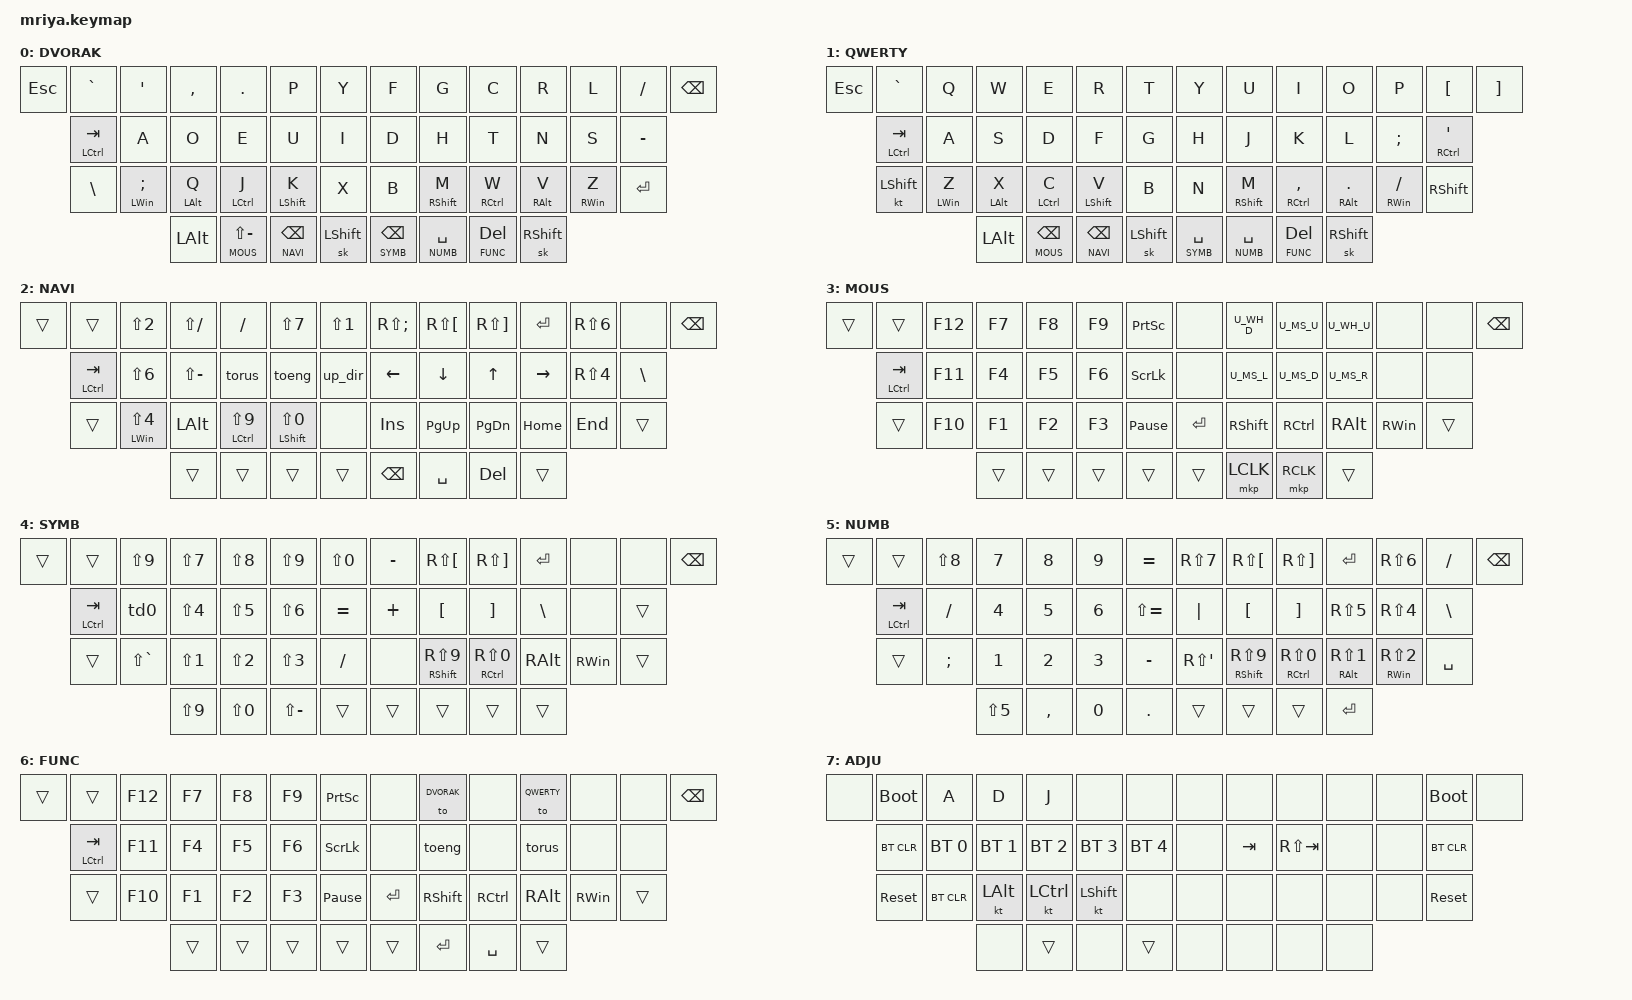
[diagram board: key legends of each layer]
#include <dt-bindings/zmk/bt.h>
#include <dt-bindings/zmk/keys.h>
#include <behaviors.dtsi>
#include "keypos_46keys_mriya.h"
#include "mouse.dtsi"

#define DVORAK 0
#define QWERTY 1
#define NAVI 2
#define MOUS 3
#define SYMB 4
#define NUMB 5
#define FUNC 6
#define ADJU 7

#define XXX &none
#define ___ &trans

#define QUICK_TAP_MS 175

&sk {  // sticky-key config
    release-after-ms = <900>;  // release after 0.6s
    quick-release;             // no double capitalization when rolling keys
};

&sl {  // sticky-layer config
    ignore-modifiers;          // allow chording sticky mods & layers
};

&lt {  // layer-tap config
    flavor = "balanced";
    tapping-term-ms = <200>;
    quick-tap-ms = <QUICK_TAP_MS>;
};

/* Homerow mods */

#define KEYS_L LT0 LT1 LT2 LT3 LT4 LT5 LM0 LM1 LM2 LM3 LM4 LM5 LB0 LB1 LB2 LB3 LB4 LB5 // left hand
#define KEYS_R RT0 RT1 RT2 RT3 RT4 RT5 RM0 RM1 RM2 RM3 RM4 RM5 RB0 RB1 RB2 RB3 RB4 RB5 // right hand
#define THUMBS LH3 LH2 LH1 LH0 RH0 RH1 RH2 RH3                                         // thumbs

/ {
    macros {
        assign: assign {
            label = "assign";
            compatible = "zmk,behavior-macro";
            #binding-cells = <0>;
            bindings = <&macro_tap>, <&kp COLON &kp EQUAL &kp SPACE>;
        };
        up_dir: up_dir {
            label = "up_dir";
            compatible = "zmk,behavior-macro";
            #binding-cells = <0>;
            bindings = <&macro_tap>, <&kp DOT &kp DOT &kp SLASH>;
        };
        torus: torus {
            label = "torus";
            compatible = "zmk,behavior-macro";
            #binding-cells = <0>;
            bindings = <&macro_tap>, <&to QWERTY>, <&kp LA(LSHFT)>;
        };
        toeng: toeng {
            label = "toeng";
            compatible = "zmk,behavior-macro";
            #binding-cells = <0>;
            bindings = <&macro_tap>, <&to DVORAK>, <&kp LA(LSHFT)>;
        };
    };

    combos {
        compatible = "zmk,combos";
        combo_qmark {
            timeout-ms = <50>;
            layers = <QWERTY>;
            key-positions = <LM2 LM3>;
            require-prior-idle-ms = <150>;
            bindings = <&kp AMPS>; /* qmark in russian map */
        };
        combo_excl {
            timeout-ms = <50>;
            layers = <QWERTY>;
            key-positions = <17 18>;
            require-prior-idle-ms = <150>;
            bindings = <&kp EXCL>;
        };
        combo_commaRus {
            timeout-ms = <50>;
            layers = <QWERTY>;
            key-positions = <21 22>;
            require-prior-idle-ms = <150>;
            bindings = <&kp QMARK>; /* comma in russian map */
        };
        combo_dotRus {
            timeout-ms = <50>;
            layers = <QWERTY>;
            key-positions = <22 23>;
            require-prior-idle-ms = <150>;
            bindings = <&kp FSLH>; /* dot in russian map */
        };

        combo_esc {
            timeout-ms = <18>;
            key-positions = <LT2 LT3>;
            require-prior-idle-ms = <150>;
            bindings = <&kp ESC>;
        };
        combo_enter {
            timeout-ms = <18>;
            key-positions = <4 5>;
            require-prior-idle-ms = <150>;
            bindings = <&kp ENTER>;
        };
//        combo_tab {
//            timeout-ms = <18>;
//            key-positions = <LM2 LM3>;
//            require-prior-idle-ms = <150>;
//            bindings = <&kp TAB>;
//        };
        combo_assign {
            timeout-ms = <18>;
            key-positions = <LM2 LM3>;
            require-prior-idle-ms = <150>;
            bindings = <&assign>;
        };
        combo_del {
            timeout-ms = <18>;
            key-positions = <RT1 RT2>;
            require-prior-idle-ms = <150>;
            bindings = <&kp DEL>;
        };
        combo_bspc {
            timeout-ms = <18>;
            key-positions = <RT2 RT3>;
            require-prior-idle-ms = <150>;
            bindings = <&kp BSPC>;
        };

        combo_lpar {
            timeout-ms = <30>;
            key-positions = <RM1 RM2>;
            require-prior-idle-ms = <150>;
            bindings = <&kp LPAR>;
        };
        combo_rpar {
            timeout-ms = <30>;
            key-positions = <RM2 RM3>;
            require-prior-idle-ms = <150>;
            bindings = <&kp RPAR>;
        };

        combo_pipe {
            timeout-ms = <30>;
            key-positions = <RM3 RB3>;
            require-prior-idle-ms = <150>;
            bindings = <&kp PIPE>;
        };
    };

    behaviors {
        td0: tap_dance_0 {
            label = "td0";
            compatible = "zmk,behavior-tap-dance";
            #binding-cells = <0>;
            tapping-term-ms = <250>;
            bindings = <&kp COLON>, <&assign>;
        };
        bhl: balanced_homerow_left {
            label = "bhl";
            compatible = "zmk,behavior-hold-tap";
            #binding-cells = <2>;
        flavor = "balanced";
        tapping-term-ms = <280>;
        quick-tap-ms = <QUICK_TAP_MS>;
        require-prior-idle-ms = <150>;
        bindings = <&kp>, <&kp>;
        hold-trigger-key-positions = <7 8 9 10 11 12 13 20 21 22 23 24 25 32 33 34 35 36 37 42 43 44 45>;
        hold-trigger-on-release;
/*            tapping-term-ms = <300>;
            quick-tap-ms = <175>;
            require-prior-idle-ms = <150>;
            flavor = "balanced";
            bindings = <&kp>, <&kp>;
            hold-trigger-key-positions = <7 8 9 10 11 12 13 20 21 22 23 24 25 32 33 34 35 36 37 42 43 44 45>;
            hold-trigger-on-release; */
        };
        bhr: balanced_homerow_right {
            label = "bhr";
            compatible = "zmk,behavior-hold-tap";
            #binding-cells = <2>;
        flavor = "balanced";
        tapping-term-ms = <280>;
        quick-tap-ms = <QUICK_TAP_MS>;
        require-prior-idle-ms = <150>;
        bindings = <&kp>, <&kp>;
        hold-trigger-key-positions = <0 1 2 3 4 5 6 14 15 16 17 18 19 26 27 28 29 30 31 38 39 40 41>;
        hold-trigger-on-release;
/*            tapping-term-ms = <300>;
            quick-tap-ms = <175>;
            require-prior-idle-ms = <150>;
            flavor = "balanced";
            bindings = <&kp>, <&kp>;
            hold-trigger-key-positions = <0 1 2 3 4 5 6 14 15 16 17 18 19 26 27 28 29 30 31 38 39 40 41>;
            hold-trigger-on-release; */
        };
        mo_tog: behavior_mo_tog {
            label = "mo_tog";
            compatible = "zmk,behavior-hold-tap";
            #binding-cells = <2>;
            flavor = "hold-preferred";
            tapping-term-ms = <200>;
            bindings = <&mo>, <&tog>;
        };
    };

    conditional_layers {
        compatible = "zmk,conditional-layers";
        tri_layer {
            if-layers = <MOUS FUNC>;
            then-layer = <ADJU>;
        };
    };

    keymap {
        compatible = "zmk,keymap";

        DVORAK {
            bindings = <
&kp ESC  &kp GRAVE      &kp SQT         &kp COMMA      &kp DOT             &kp P          &kp Y                &kp F           &kp G           &kp C          &kp R        &kp L           &kp SLASH          &kp BSPC
         &mt LCTRL TAB  &kp A           &kp O          &kp E               &kp U          &kp I                &kp D           &kp H           &kp T          &kp N        &kp S           &kp MINUS
         &kp BSLH       &bhl LWIN SEMI  &bhl LALT Q    &bhl LCTRL J        &bhl LSHFT K   &kp X                &kp B           &bhr RSHFT M    &bhr RCTRL W   &bhr RALT V  &bhr RWIN Z     &kp ENTER
                                        &kp LALT       &lt MOUS LS(MINUS)  &lt NAVI BSPC  &sk LSHFT            &lt SYMB BSPC   &lt NUMB SPACE  &lt FUNC DEL   &sk RSHFT
            >;
        };

        QWERTY {
            bindings = <
&kp ESC  &kp GRAVE      &kp Q           &kp W          &kp E          &kp R          &kp T                     &kp Y           &kp U           &kp I             &kp O          &kp P           &kp LBKT      &kp RBKT
         &mt LCTRL TAB  &kp A           &kp S          &kp D          &kp F          &kp G                     &kp H           &kp J           &kp K             &kp L          &kp SEMI        &mt RCTRL SQT
         &kt LSHFT      &bhl LWIN Z     &bhl LALT X    &bhl LCTRL C   &bhl LSHFT V   &kp B                     &kp N           &bhr RSHFT M    &bhr RCTRL COMMA  &bhr RALT DOT  &bhr RWIN FSLH  &kp RSHFT
                                        &kp LALT       &lt MOUS BSPC  &lt NAVI BSPC  &sk LSHFT                 &lt SYMB SPACE  &lt NUMB SPACE  &lt FUNC DEL      &sk RSHFT  
            >;
        };

        NAVI {
// for russian layout
// S(KC_4) -> ;    S(KC_2) -> "    KC_SLSH -> .   S(KC_SLSH) -> ,  S(KC_7) -> ?    S(KC_1) -> !   S(KC_6) -> :
            bindings = <
&trans   &trans         &kp LS(N2)        &kp LS(SLASH)  &kp SLASH          &kp LS(N7)         &kp LS(N1)      &kp RS(SEMI)  &kp RS(LBKT)    &kp RS(RBKT)      &kp ENTER      &kp RS(N6)      &none           &kp BSPC
         &mt LCTRL TAB  &kp LS(N6)        &kp LS(MINUS)  &torus             &toeng             &up_dir         &kp LEFT      &kp DOWN        &kp UP            &kp RIGHT      &kp RS(N4)      &kp BSLH
         &trans         &bhl LWIN LS(N4)  &kp LALT       &bhl LCTRL LS(N9)  &bhl LSHFT LS(N0)  &none           &kp INS       &kp PG_UP       &kp PG_DN         &kp HOME       &kp END         &trans
                                          &trans         &trans             &trans             &trans          &kp BSPC      &kp SPACE       &kp DEL           &trans
            >;
        };

        MOUS {
            bindings = <
&trans   &trans         &kp F12         &kp F7         &kp F8         &kp F9         &kp PSCRN                 &none         U_WH_D         U_MS_U             U_WH_U         &none           &none           &kp BSPC
         &mt LCTRL TAB  &kp F11         &kp F4         &kp F5         &kp F6         &kp SLCK                  &none         U_MS_L         U_MS_D             U_MS_R         &none           &none
         &trans         &kp F10         &kp F1         &kp F2         &kp F3         &kp PAUSE_BREAK           &kp ENTER     &kp RSHFT      &kp RCTRL          &kp RALT       &kp RWIN        &trans
                                        &trans         &trans         &trans         &trans                    &trans        &mkp LCLK      &mkp RCLK          &trans
            >;
        };

        SYMB {
            bindings = <
&trans   &trans         &kp LS(N9)      &kp LS(N7)     &kp LS(N8)     &kp LS(N9)     &kp LS(N0)                &kp MINUS    &kp RS(LBKT)       &kp RS(RBKT)       &kp ENTER      &none           &none            &kp BSPC
         &mt LCTRL TAB  &td0            &kp LS(N4)     &kp LS(N5)     &kp LS(N6)     &kp EQUAL                 &kp PLUS     &kp LBKT           &kp RBKT           &kp BSLH       &none           &trans
         &trans         &kp LS(GRAVE)   &kp LS(N1)     &kp LS(N2)     &kp LS(N3)     &kp SLASH                 &none        &bhr RSHFT RS(N9)  &bhr RCTRL RS(N0)  &kp RALT       &kp RWIN        &trans
                                        &kp LS(N9)     &kp LS(N0)     &kp LS(MINUS)  &trans                    &trans       &trans             &trans             &trans
            >;
        };

        NUMB {
            bindings = <
&trans   &trans         &kp LS(N8)      &kp N7         &kp N8         &kp N9         &kp EQUAL                 &kp RS(N7)   &kp RS(LBKT)       &kp RS(RBKT)       &kp ENTER         &kp RS(N6)        &kp SLASH    &kp BSPC
         &mt LCTRL TAB  &kp SLASH       &kp N4         &kp N5         &kp N6         &kp LS(EQUAL)             &kp PIPE     &kp LBKT           &kp RBKT           &kp RS(N5)        &kp RS(N4)        &kp BSLH
         &trans         &kp SEMI        &kp N1         &kp N2         &kp N3         &kp MINUS                 &kp RS(SQT)  &bhr RSHFT RS(N9)  &bhr RCTRL RS(N0)  &bhr RALT RS(N1)  &bhr RWIN RS(N2)  &kp SPACE
                                        &kp LS(N5)     &kp COMMA      &kp N0         &kp DOT                   &trans       &trans             &trans             &kp ENTER
            >;
        };

        FUNC {
            bindings = <
&trans   &trans         &kp F12         &kp F7         &kp F8         &kp F9         &kp PSCRN                 &none        &to DVORAK     &none              &to QWERTY     &none           &none            &kp BSPC
         &mt LCTRL TAB  &kp F11         &kp F4         &kp F5         &kp F6         &kp SLCK                  &none        &toeng         &none              &torus         &none           &none
         &trans         &kp F10         &kp F1         &kp F2         &kp F3         &kp PAUSE_BREAK           &kp ENTER    &kp RSHFT      &kp RCTRL          &kp RALT       &kp RWIN        &trans
                                        &trans         &trans         &trans         &trans                    &trans       &kp ENTER      &kp SPACE          &trans
            >;
        };

        ADJU {
            bindings = <
&none    &bootloader    &kp A           &kp D          &kp J          &none         &none                      &none         &none         &none              &none          &none           &bootloader      &none
         &bt BT_CLR     &bt BT_SEL 0    &bt BT_SEL 1   &bt BT_SEL 2   &bt BT_SEL 3  &bt BT_SEL 4               &none         &kp TAB       &kp RS(TAB)        &none          &none           &bt BT_CLR
         &sys_reset     &bt BT_CLR      &kt LALT       &kt LCTRL      &kt LSHFT     &none                      &none         &none         &none              &none          &none           &sys_reset
                                        &none          &trans         &none         &trans                     &none         &none         &none              &none
            >;
        };

    };
};
